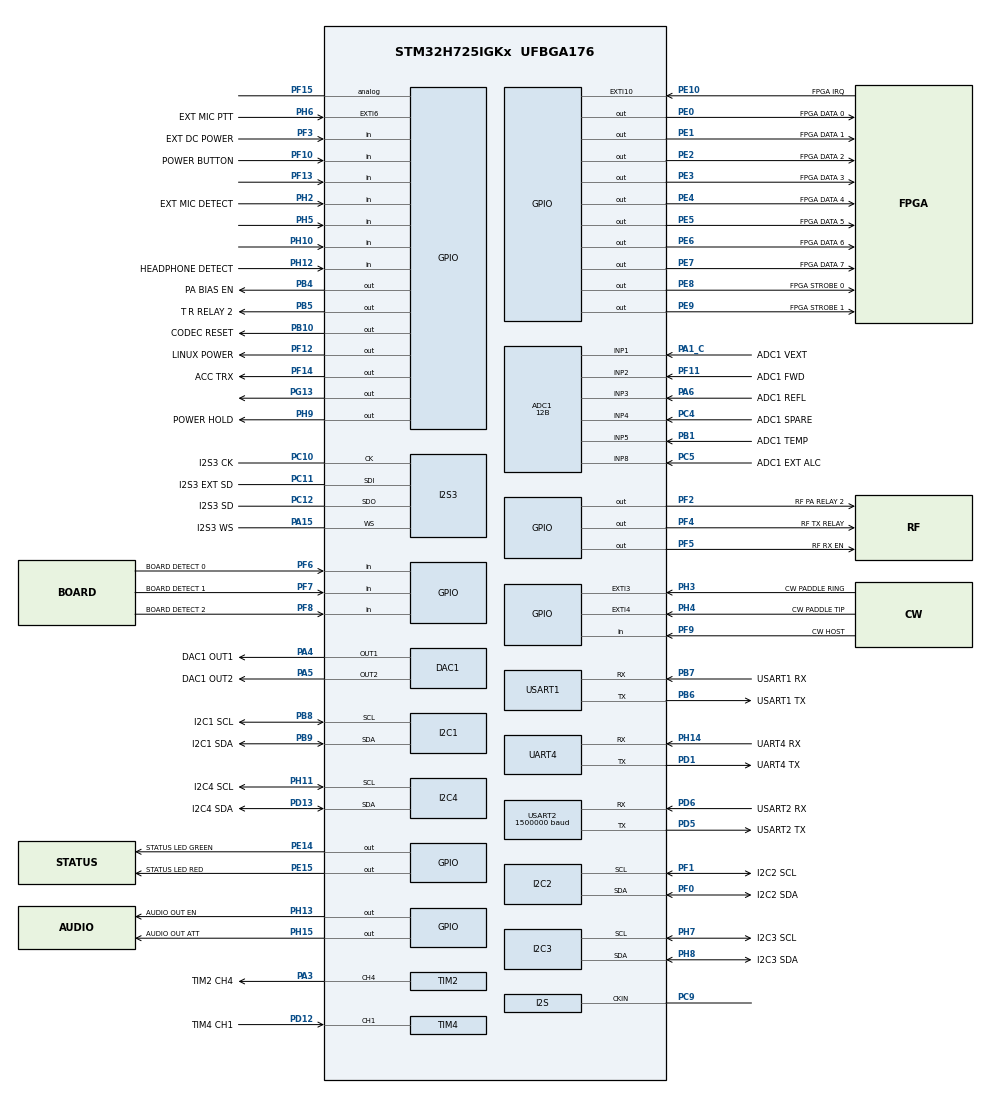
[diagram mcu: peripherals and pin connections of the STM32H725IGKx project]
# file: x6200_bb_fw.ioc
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ADC1.Channel-0\#ChannelRegularConversion=ADC_CHANNEL_1
ADC1.Channel-1\#ChannelRegularConversion=ADC_CHANNEL_2
ADC1.Channel-2\#ChannelRegularConversion=ADC_CHANNEL_3
ADC1.Channel-3\#ChannelRegularConversion=ADC_CHANNEL_4
ADC1.Channel-4\#ChannelRegularConversion=ADC_CHANNEL_5
ADC1.Channel-5\#ChannelRegularConversion=ADC_CHANNEL_8
ADC1.ClockPrescaler=ADC_CLOCK_ASYNC_DIV32
ADC1.ContinuousConvMode=ENABLE
ADC1.ConversionDataManagement=ADC_CONVERSIONDATA_DMA_CIRCULAR
ADC1.NbrOfConversion=6
ADC1.NbrOfConversionFlag=1
ADC1.OffsetNumber-0\#ChannelRegularConversion=ADC_OFFSET_NONE
ADC1.OffsetNumber-1\#ChannelRegularConversion=ADC_OFFSET_NONE
ADC1.OffsetNumber-2\#ChannelRegularConversion=ADC_OFFSET_NONE
ADC1.OffsetNumber-3\#ChannelRegularConversion=ADC_OFFSET_NONE
ADC1.OffsetNumber-4\#ChannelRegularConversion=ADC_OFFSET_NONE
ADC1.OffsetNumber-5\#ChannelRegularConversion=ADC_OFFSET_NONE
ADC1.OffsetSignedSaturation-0\#ChannelRegularConversion=DISABLE
ADC1.OffsetSignedSaturation-1\#ChannelRegularConversion=DISABLE
ADC1.OffsetSignedSaturation-2\#ChannelRegularConversion=DISABLE
ADC1.OffsetSignedSaturation-3\#ChannelRegularConversion=DISABLE
ADC1.OffsetSignedSaturation-4\#ChannelRegularConversion=DISABLE
ADC1.OffsetSignedSaturation-5\#ChannelRegularConversion=DISABLE
ADC1.Rank-0\#ChannelRegularConversion=1
ADC1.Rank-1\#ChannelRegularConversion=2
ADC1.Rank-2\#ChannelRegularConversion=3
ADC1.Rank-3\#ChannelRegularConversion=4
ADC1.Rank-4\#ChannelRegularConversion=5
ADC1.Rank-5\#ChannelRegularConversion=6
ADC1.Resolution=ADC_RESOLUTION_12B
ADC1.SamplingTime-0\#ChannelRegularConversion=ADC_SAMPLETIME_32CYCLES_5
ADC1.SamplingTime-1\#ChannelRegularConversion=ADC_SAMPLETIME_32CYCLES_5
ADC1.SamplingTime-2\#ChannelRegularConversion=ADC_SAMPLETIME_32CYCLES_5
ADC1.SamplingTime-3\#ChannelRegularConversion=ADC_SAMPLETIME_32CYCLES_5
ADC1.SamplingTime-4\#ChannelRegularConversion=ADC_SAMPLETIME_32CYCLES_5
ADC1.SamplingTime-5\#ChannelRegularConversion=ADC_SAMPLETIME_32CYCLES_5
ADC1.master=1
ARM.CMSIS-DSP.1.18.0.CMSISJjDSP=Source
CORTEX_M7.AccessPermission_Spec=MPU_REGION_FULL_ACCESS
CORTEX_M7.BaseAddress_Spec=0x30000000
CORTEX_M7.CPU_DCache=Enabled
CORTEX_M7.CPU_ICache=Enabled
CORTEX_M7.DisableExec_Spec=MPU_INSTRUCTION_ACCESS_DISABLE
CORTEX_M7.Enable_S-Cortex_Memory_Protection_Unit_Region1_Settings_S=__NULL
CORTEX_M7.Enable_S-Cortex_Memory_Protection_Unit_Region2_Settings_S=__NULL
CORTEX_M7.Enable_S-Cortex_Memory_Protection_Unit_Region3_Settings_S=__NULL
CORTEX_M7.Enable_S-Cortex_Memory_Protection_Unit_Region4_Settings_S=__NULL
CORTEX_M7.Enable_S-Cortex_Memory_Protection_Unit_Region5_Settings_S=__NULL
CORTEX_M7.Enable_Spec=MPU_REGION_ENABLE
CORTEX_M7.Size_Spec=MPU_REGION_SIZE_8KB
CORTEX_M7.SubRegionDisable_Spec=0x0
CORTEX_M7.TypeExtField_Spec=MPU_TEX_LEVEL1
CORTEX_M7.default_mode_Activation=1
CRC.InputDataFormat=CRC_INPUTDATA_FORMAT_WORDS
DAC1.DAC_Channel-DAC_OUT1=DAC_CHANNEL_1
DAC1.DAC_Channel-DAC_OUT2=DAC_CHANNEL_2
DAC1.DAC_Trigger-DAC_OUT1=DAC_TRIGGER_NONE
Dma.ADC1.2.Direction=DMA_PERIPH_TO_MEMORY
Dma.ADC1.2.EventEnable=DISABLE
Dma.ADC1.2.FIFOMode=DMA_FIFOMODE_DISABLE
Dma.ADC1.2.Instance=DMA1_Stream7
Dma.ADC1.2.MemDataAlignment=DMA_MDATAALIGN_HALFWORD
Dma.ADC1.2.MemInc=DMA_MINC_ENABLE
Dma.ADC1.2.Mode=DMA_CIRCULAR
Dma.ADC1.2.PeriphDataAlignment=DMA_PDATAALIGN_HALFWORD
Dma.ADC1.2.PeriphInc=DMA_PINC_DISABLE
Dma.ADC1.2.Polarity=HAL_DMAMUX_REQ_GEN_RISING
Dma.ADC1.2.Priority=DMA_PRIORITY_LOW
Dma.ADC1.2.RequestNumber=1
Dma.ADC1.2.SignalID=NONE
Dma.ADC1.2.SyncEnable=DISABLE
Dma.ADC1.2.SyncPolarity=HAL_DMAMUX_SYNC_NO_EVENT
Dma.ADC1.2.SyncRequestNumber=1
Dma.ADC1.2.SyncSignalID=NONE
Dma.Request0=SPI3_RX
Dma.Request1=SPI3_TX
Dma.Request2=ADC1
Dma.Request3=USART2_TX
Dma.Request4=USART1_TX
Dma.Request5=USART2_RX
Dma.SPI3_RX.0.Direction=DMA_PERIPH_TO_MEMORY
Dma.SPI3_RX.0.EventEnable=DISABLE
Dma.SPI3_RX.0.FIFOMode=DMA_FIFOMODE_ENABLE
Dma.SPI3_RX.0.FIFOThreshold=DMA_FIFO_THRESHOLD_HALFFULL
Dma.SPI3_RX.0.Instance=DMA1_Stream0
Dma.SPI3_RX.0.MemBurst=DMA_MBURST_SINGLE
Dma.SPI3_RX.0.MemDataAlignment=DMA_MDATAALIGN_WORD
Dma.SPI3_RX.0.MemInc=DMA_MINC_ENABLE
Dma.SPI3_RX.0.Mode=DMA_CIRCULAR
Dma.SPI3_RX.0.PeriphBurst=DMA_PBURST_SINGLE
Dma.SPI3_RX.0.PeriphDataAlignment=DMA_PDATAALIGN_WORD
Dma.SPI3_RX.0.PeriphInc=DMA_PINC_DISABLE
Dma.SPI3_RX.0.Polarity=HAL_DMAMUX_REQ_GEN_RISING
Dma.SPI3_RX.0.Priority=DMA_PRIORITY_HIGH
Dma.SPI3_RX.0.RequestNumber=1
Dma.SPI3_RX.0.SignalID=NONE
Dma.SPI3_RX.0.SyncEnable=DISABLE
Dma.SPI3_RX.0.SyncPolarity=HAL_DMAMUX_SYNC_NO_EVENT
Dma.SPI3_RX.0.SyncRequestNumber=1
Dma.SPI3_RX.0.SyncSignalID=NONE
Dma.SPI3_TX.1.Direction=DMA_MEMORY_TO_PERIPH
Dma.SPI3_TX.1.EventEnable=DISABLE
Dma.SPI3_TX.1.FIFOMode=DMA_FIFOMODE_ENABLE
Dma.SPI3_TX.1.FIFOThreshold=DMA_FIFO_THRESHOLD_HALFFULL
Dma.SPI3_TX.1.Instance=DMA1_Stream5
Dma.SPI3_TX.1.MemBurst=DMA_MBURST_SINGLE
Dma.SPI3_TX.1.MemDataAlignment=DMA_MDATAALIGN_WORD
Dma.SPI3_TX.1.MemInc=DMA_MINC_ENABLE
Dma.SPI3_TX.1.Mode=DMA_CIRCULAR
Dma.SPI3_TX.1.PeriphBurst=DMA_PBURST_SINGLE
Dma.SPI3_TX.1.PeriphDataAlignment=DMA_PDATAALIGN_WORD
Dma.SPI3_TX.1.PeriphInc=DMA_PINC_DISABLE
Dma.SPI3_TX.1.Polarity=HAL_DMAMUX_REQ_GEN_RISING
Dma.SPI3_TX.1.Priority=DMA_PRIORITY_HIGH
Dma.SPI3_TX.1.RequestNumber=1
Dma.SPI3_TX.1.SignalID=NONE
Dma.SPI3_TX.1.SyncEnable=DISABLE
Dma.SPI3_TX.1.SyncPolarity=HAL_DMAMUX_SYNC_NO_EVENT
Dma.SPI3_TX.1.SyncRequestNumber=1
Dma.SPI3_TX.1.SyncSignalID=NONE
Dma.USART1_TX.4.Direction=DMA_MEMORY_TO_PERIPH
Dma.USART1_TX.4.EventEnable=DISABLE
Dma.USART1_TX.4.FIFOMode=DMA_FIFOMODE_DISABLE
Dma.USART1_TX.4.Instance=DMA1_Stream2
Dma.USART1_TX.4.MemDataAlignment=DMA_MDATAALIGN_BYTE
Dma.USART1_TX.4.MemInc=DMA_MINC_ENABLE
Dma.USART1_TX.4.Mode=DMA_NORMAL
Dma.USART1_TX.4.PeriphDataAlignment=DMA_PDATAALIGN_BYTE
Dma.USART1_TX.4.PeriphInc=DMA_PINC_DISABLE
Dma.USART1_TX.4.Polarity=HAL_DMAMUX_REQ_GEN_RISING
Dma.USART1_TX.4.Priority=DMA_PRIORITY_LOW
Dma.USART1_TX.4.RequestNumber=1
Dma.USART1_TX.4.SignalID=NONE
Dma.USART1_TX.4.SyncEnable=DISABLE
Dma.USART1_TX.4.SyncPolarity=HAL_DMAMUX_SYNC_NO_EVENT
Dma.USART1_TX.4.SyncRequestNumber=1
Dma.USART1_TX.4.SyncSignalID=NONE
Dma.USART2_RX.5.Direction=DMA_PERIPH_TO_MEMORY
Dma.USART2_RX.5.EventEnable=DISABLE
Dma.USART2_RX.5.FIFOMode=DMA_FIFOMODE_DISABLE
Dma.USART2_RX.5.Instance=DMA1_Stream3
Dma.USART2_RX.5.MemDataAlignment=DMA_MDATAALIGN_BYTE
Dma.USART2_RX.5.MemInc=DMA_MINC_ENABLE
Dma.USART2_RX.5.Mode=DMA_CIRCULAR
Dma.USART2_RX.5.PeriphDataAlignment=DMA_PDATAALIGN_BYTE
Dma.USART2_RX.5.PeriphInc=DMA_PINC_DISABLE
Dma.USART2_RX.5.Polarity=HAL_DMAMUX_REQ_GEN_RISING
Dma.USART2_RX.5.Priority=DMA_PRIORITY_VERY_HIGH
Dma.USART2_RX.5.RequestNumber=1
Dma.USART2_RX.5.SignalID=NONE
Dma.USART2_RX.5.SyncEnable=DISABLE
Dma.USART2_RX.5.SyncPolarity=HAL_DMAMUX_SYNC_NO_EVENT
Dma.USART2_RX.5.SyncRequestNumber=1
Dma.USART2_RX.5.SyncSignalID=NONE
Dma.USART2_TX.3.Direction=DMA_MEMORY_TO_PERIPH
Dma.USART2_TX.3.EventEnable=DISABLE
Dma.USART2_TX.3.FIFOMode=DMA_FIFOMODE_DISABLE
Dma.USART2_TX.3.Instance=DMA1_Stream1
Dma.USART2_TX.3.MemDataAlignment=DMA_MDATAALIGN_BYTE
Dma.USART2_TX.3.MemInc=DMA_MINC_ENABLE
Dma.USART2_TX.3.Mode=DMA_NORMAL
Dma.USART2_TX.3.PeriphDataAlignment=DMA_PDATAALIGN_BYTE
Dma.USART2_TX.3.PeriphInc=DMA_PINC_DISABLE
Dma.USART2_TX.3.Polarity=HAL_DMAMUX_REQ_GEN_RISING
Dma.USART2_TX.3.Priority=DMA_PRIORITY_VERY_HIGH
Dma.USART2_TX.3.RequestNumber=1
Dma.USART2_TX.3.SignalID=NONE
Dma.USART2_TX.3.SyncEnable=DISABLE
Dma.USART2_TX.3.SyncPolarity=HAL_DMAMUX_SYNC_NO_EVENT
Dma.USART2_TX.3.SyncRequestNumber=1
Dma.USART2_TX.3.SyncSignalID=NONE
I2C1.Timing=0x307075B1
I2C2.Timing=0x307075B1
I2C3.CustomTiming=Enabled
I2C3.OwnAddress=0x72
I2C3.Timing=0x00B03FDB
I2C4.Timing=0x307075B1
I2S3.AudioFreq=I2S_AUDIOFREQ_48K
I2S3.DataFormat=I2S_DATAFORMAT_32B
I2S3.ErrorAudioFreq=0.0 %
I2S3.Instance=SPI$Index
I2S3.RealAudioFreq=48.0 KHz
Mcu.Family=STM32H7
Mcu.Name=STM32H725IGKx
Mcu.Package=UFBGA176
NVIC.DMA1_Stream0_IRQn=true\:2\:0\:true\:false\:true\:false\:true\:true
NVIC.DMA1_Stream1_IRQn=true\:5\:0\:true\:false\:true\:false\:true\:true
NVIC.DMA1_Stream2_IRQn=true\:9\:0\:true\:false\:true\:false\:true\:true
NVIC.DMA1_Stream3_IRQn=true\:5\:0\:true\:false\:true\:false\:true\:true
NVIC.DMA1_Stream5_IRQn=true\:2\:0\:true\:false\:true\:false\:true\:true
NVIC.DMA1_Stream7_IRQn=true\:1\:0\:true\:false\:true\:false\:true\:true
NVIC.EXTI15_10_IRQn=true\:0\:0\:true\:false\:true\:true\:true\:true
NVIC.EXTI3_IRQn=true\:1\:0\:true\:false\:true\:true\:true\:true
NVIC.EXTI4_IRQn=true\:1\:0\:true\:false\:true\:true\:true\:true
NVIC.EXTI9_5_IRQn=true\:3\:0\:true\:false\:true\:true\:true\:true
NVIC.I2C1_ER_IRQn=true\:8\:0\:true\:false\:true\:true\:true\:true
NVIC.I2C1_EV_IRQn=true\:8\:0\:true\:false\:true\:true\:true\:true
NVIC.I2C3_ER_IRQn=true\:5\:0\:true\:false\:true\:true\:true\:true
NVIC.I2C3_EV_IRQn=true\:5\:0\:true\:false\:true\:true\:true\:true
NVIC.PriorityGroup=NVIC_PRIORITYGROUP_4
NVIC.TIM17_IRQn=true\:3\:0\:true\:false\:true\:true\:true\:true
NVIC.TIM4_IRQn=true\:1\:0\:true\:false\:true\:true\:true\:true
NVIC.TIM6_DAC_IRQn=true\:8\:0\:true\:false\:true\:true\:true\:true
NVIC.TIM7_IRQn=true\:1\:0\:true\:false\:true\:true\:true\:true
NVIC.USART1_IRQn=true\:9\:0\:true\:false\:true\:true\:true\:true
NVIC.USART2_IRQn=true\:5\:0\:true\:false\:true\:true\:true\:true
PA15(JTDI).GPIO_Label=I2S3 WS
PA15(JTDI).GPIO_PuPd=GPIO_PULLUP
PA15(JTDI).GPIO_Speed=GPIO_SPEED_FREQ_VERY_HIGH
PA15(JTDI).Mode=Full_Duplex_Master
PA15(JTDI).Signal=I2S3_WS
PA1_C.GPIO_Label=ADC1 VEXT
PA1_C.Signal=ADCx_INP1
PA3.GPIO_Label=TIM2 CH4
PA3.Signal=S_TIM2_CH4
PA4.GPIO_Label=DAC1 OUT1
PA4.Signal=COMP_DAC11_group
PA5.GPIO_Label=DAC1 OUT2
PA5.Signal=COMP_DAC12_group
PA6.GPIO_Label=ADC1 REFL
PA6.Signal=ADCx_INP3
PB1.GPIO_Label=ADC1 TEMP
PB1.Signal=ADCx_INP5
PB10.GPIO_Label=CODEC RESET
PB10.Signal=GPIO_Output
PB4(NJTRST).GPIO_Label=PA BIAS EN
PB4(NJTRST).Signal=GPIO_Output
PB5.GPIO_Label=T R RELAY 2
PB5.Signal=GPIO_Output
PB6.GPIO_Label=USART1 TX
PB6.Mode=Asynchronous
PB6.Signal=USART1_TX
PB7.GPIO_Label=USART1 RX
PB7.Mode=Asynchronous
PB7.Signal=USART1_RX
PB8.GPIO_Label=I2C1 SCL
PB8.Mode=I2C
PB8.Signal=I2C1_SCL
PB9.GPIO_Label=I2C1 SDA
PB9.Mode=I2C
PB9.Signal=I2C1_SDA
PC10.GPIO_Label=I2S3 CK
PC10.GPIO_PuPd=GPIO_PULLUP
PC10.GPIO_Speed=GPIO_SPEED_FREQ_VERY_HIGH
PC10.Mode=Full_Duplex_Master
PC10.Signal=I2S3_CK
PC11.GPIO_Label=I2S3 EXT SD
PC11.GPIO_PuPd=GPIO_PULLUP
PC11.GPIO_Speed=GPIO_SPEED_FREQ_VERY_HIGH
PC11.Mode=Full_Duplex_Master
PC11.Signal=I2S3_SDI
PC12.GPIO_Label=I2S3 SD
PC12.GPIO_PuPd=GPIO_PULLUP
PC12.GPIO_Speed=GPIO_SPEED_FREQ_VERY_HIGH
PC12.Mode=Full_Duplex_Master
PC12.Signal=I2S3_SDO
PC4.GPIO_Label=ADC1 SPARE
PC4.Signal=ADCx_INP4
PC5.GPIO_Label=ADC1 EXT ALC
PC5.Signal=ADCx_INP8
PC9.Mode=Audio_ClockIn
PC9.Signal=I2S_CKIN
PD1.GPIO_Label=UART4 TX
PD1.Mode=Asynchronous
PD1.Signal=UART4_TX
PD12.GPIO_Label=TIM4 CH1
PD12.Signal=S_TIM4_CH1
PD13.GPIO_Label=I2C4 SDA
PD13.Mode=I2C
PD13.Signal=I2C4_SDA
PD5.GPIO_Label=USART2 TX
PD5.Mode=Asynchronous
PD5.Signal=USART2_TX
PD6.GPIO_Label=USART2 RX
PD6.Mode=Asynchronous
PD6.Signal=USART2_RX
PE0.GPIO_Label=FPGA DATA 0
PE0.GPIO_PuPd=GPIO_PULLUP
PE0.GPIO_Speed=GPIO_SPEED_FREQ_MEDIUM
PE0.Signal=GPIO_Output
PE1.GPIO_Label=FPGA DATA 1
PE1.GPIO_PuPd=GPIO_PULLUP
PE1.GPIO_Speed=GPIO_SPEED_FREQ_MEDIUM
PE1.Signal=GPIO_Output
PE10.GPIO_Label=FPGA IRQ
PE10.GPIO_PuPd=GPIO_PULLUP
PE10.Signal=GPXTI10
PE14.GPIO_Label=STATUS LED GREEN
PE14.GPIO_ModeDefaultOutputPP=GPIO_MODE_OUTPUT_OD
PE14.GPIO_PuPd=GPIO_NOPULL
PE14.PinState=GPIO_PIN_SET
PE14.Signal=GPIO_Output
PE15.GPIO_Label=STATUS LED RED
PE15.GPIO_ModeDefaultOutputPP=GPIO_MODE_OUTPUT_OD
PE15.GPIO_PuPd=GPIO_NOPULL
PE15.PinState=GPIO_PIN_SET
PE15.Signal=GPIO_Output
PE2.GPIO_Label=FPGA DATA 2
PE2.GPIO_PuPd=GPIO_PULLUP
PE2.GPIO_Speed=GPIO_SPEED_FREQ_MEDIUM
PE2.Signal=GPIO_Output
PE3.GPIO_Label=FPGA DATA 3
PE3.GPIO_PuPd=GPIO_PULLUP
PE3.GPIO_Speed=GPIO_SPEED_FREQ_MEDIUM
PE3.Signal=GPIO_Output
PE4.GPIO_Label=FPGA DATA 4
PE4.GPIO_PuPd=GPIO_PULLUP
PE4.GPIO_Speed=GPIO_SPEED_FREQ_MEDIUM
PE4.Signal=GPIO_Output
PE5.GPIO_Label=FPGA DATA 5
PE5.GPIO_PuPd=GPIO_PULLUP
PE5.GPIO_Speed=GPIO_SPEED_FREQ_MEDIUM
PE5.Signal=GPIO_Output
PE6.GPIO_Label=FPGA DATA 6
PE6.GPIO_PuPd=GPIO_PULLUP
PE6.GPIO_Speed=GPIO_SPEED_FREQ_MEDIUM
PE6.Signal=GPIO_Output
PE7.GPIO_Label=FPGA DATA 7
PE7.GPIO_PuPd=GPIO_PULLUP
PE7.GPIO_Speed=GPIO_SPEED_FREQ_MEDIUM
PE7.Signal=GPIO_Output
PE8.GPIO_Label=FPGA STROBE 0
PE8.GPIO_PuPd=GPIO_PULLUP
PE8.GPIO_Speed=GPIO_SPEED_FREQ_MEDIUM
PE8.Signal=GPIO_Output
PE9.GPIO_Label=FPGA STROBE 1
PE9.GPIO_PuPd=GPIO_PULLUP
PE9.GPIO_Speed=GPIO_SPEED_FREQ_MEDIUM
PE9.Signal=GPIO_Output
PF0.GPIO_Label=I2C2 SDA
PF0.Mode=I2C
PF0.Signal=I2C2_SDA
PF1.GPIO_Label=I2C2 SCL
PF1.Mode=I2C
PF1.Signal=I2C2_SCL
PF10.GPIO_Label=POWER BUTTON
PF10.GPIO_PuPd=GPIO_PULLUP
PF10.Signal=GPIO_Input
PF11.GPIO_Label=ADC1 FWD
PF11.Mode=IN2-Single-Ended
PF11.Signal=ADC1_INP2
PF12.GPIO_Label=LINUX POWER
PF12.PinState=GPIO_PIN_SET
PF12.Signal=GPIO_Output
PF13.GPIO_PuPd=GPIO_PULLUP
PF13.Signal=GPIO_Input
PF14.GPIO_Label=ACC TRX
PF14.GPIO_PuPd=GPIO_PULLUP
PF14.Signal=GPIO_Output
PF15.Signal=GPIO_Analog
PF2.GPIO_Label=RF PA RELAY 2
PF2.Signal=GPIO_Output
PF3.GPIO_Label=EXT DC POWER
PF3.Signal=GPIO_Input
PF4.GPIO_Label=RF TX RELAY
PF4.Signal=GPIO_Output
PF5.GPIO_Label=RF RX EN
PF5.Signal=GPIO_Output
PF6.GPIO_Label=BOARD DETECT 0
PF6.GPIO_PuPd=GPIO_PULLUP
PF6.Signal=GPIO_Input
PF7.GPIO_Label=BOARD DETECT 1
PF7.GPIO_PuPd=GPIO_PULLUP
PF7.Signal=GPIO_Input
PF8.GPIO_Label=BOARD DETECT 2
PF8.GPIO_PuPd=GPIO_PULLUP
PF8.Signal=GPIO_Input
PF9.GPIO_Label=CW HOST
PF9.GPIO_PuPd=GPIO_PULLUP
PF9.Signal=GPIO_Input
PG13.PinState=GPIO_PIN_SET
PG13.Signal=GPIO_Output
PH0-OSC_IN.Mode=HSE-External-Oscillator
PH0-OSC_IN.Signal=RCC_OSC_IN
PH1-OSC_OUT.Mode=HSE-External-Oscillator
PH1-OSC_OUT.Signal=RCC_OSC_OUT
PH10.GPIO_PuPd=GPIO_PULLUP
PH10.Signal=GPIO_Input
PH11.GPIO_Label=I2C4 SCL
PH11.Mode=I2C
PH11.Signal=I2C4_SCL
PH12.GPIO_Label=HEADPHONE DETECT
PH12.GPIO_PuPd=GPIO_PULLUP
PH12.Signal=GPIO_Input
PH13.GPIO_Label=AUDIO OUT EN
PH13.Signal=GPIO_Output
PH14.GPIO_Label=UART4 RX
PH14.Mode=Asynchronous
PH14.Signal=UART4_RX
PH15.GPIO_Label=AUDIO OUT ATT
PH15.Signal=GPIO_Output
PH2.GPIO_Label=EXT MIC DETECT
PH2.GPIO_PuPd=GPIO_PULLUP
PH2.Signal=GPIO_Input
PH3.GPIO_Label=CW PADDLE RING
PH3.GPIO_ModeDefaultEXTI=GPIO_MODE_IT_RISING_FALLING
PH3.GPIO_PuPd=GPIO_PULLUP
PH3.Signal=GPXTI3
PH4.GPIO_Label=CW PADDLE TIP
PH4.GPIO_ModeDefaultEXTI=GPIO_MODE_IT_RISING_FALLING
PH4.GPIO_PuPd=GPIO_PULLUP
PH4.Signal=GPXTI4
PH5.Signal=GPIO_Input
PH6.GPIO_Label=EXT MIC PTT
PH6.GPIO_ModeDefaultEXTI=GPIO_MODE_IT_RISING_FALLING
PH6.GPIO_PuPd=GPIO_PULLUP
PH6.Signal=GPXTI6
PH7.GPIO_Label=I2C3 SCL
PH7.Mode=I2C
PH7.Signal=I2C3_SCL
PH8.GPIO_Label=I2C3 SDA
PH8.Mode=I2C
PH8.Signal=I2C3_SDA
PH9.GPIO_Label=POWER HOLD
PH9.PinState=GPIO_PIN_SET
PH9.Signal=GPIO_Output
ProjectManager.HeapSize=0x200
ProjectManager.StackSize=0x400
ProjectManager.TargetToolchain=CMake
RCC.ADCFreq_Value=96000671.38671875
RCC.APB1Freq_Value=120000000
RCC.APB2Freq_Value=120000000
RCC.APB3Freq_Value=120000000
RCC.APB4Freq_Value=120000000
RCC.CortexFreq_Value=480000000
RCC.D1PPRE=RCC_APB3_DIV2
RCC.D2PPRE1=RCC_APB1_DIV2
RCC.D2PPRE2=RCC_APB2_DIV2
RCC.D3PPRE=RCC_APB4_DIV2
RCC.DIVM1=5
RCC.DIVM2=2
RCC.DIVN1=96
RCC.DIVN2=15
RCC.DIVP1=1
RCC.EXTERNAL_CLOCK_VALUE=12288000
RCC.HCLKFreq_Value=240000000
RCC.HPRE=RCC_HCLK_DIV2
RCC.HSE_VALUE=25000000
RCC.PLL2FRACN=2950
RCC.PLLFRACN=0
RCC.PLLSourceVirtual=RCC_PLLSOURCE_HSE
RCC.RCC_TIM_PRescaler_Selection=RCC_TIMPRES_DESACTIVATED
RCC.SPI123CLockSelection=RCC_SPI123CLKSOURCE_PIN
RCC.SYSCLKFreq_VALUE=480000000
RCC.SYSCLKSource=RCC_SYSCLKSOURCE_PLLCLK
RCC.SupplySource=PWR_SMPS_2V5_SUPPLIES_EXT_AND_LDO
RCC.USBFreq_Value=240000000
SH.ADCx_INP1.0=ADC1_INP1,IN1-Single-Ended
SH.ADCx_INP3.0=ADC1_INP3,IN3-Single-Ended
SH.ADCx_INP4.0=ADC1_INP4,IN4-Single-Ended
SH.ADCx_INP5.0=ADC1_INP5,IN5-Single-Ended
SH.ADCx_INP8.0=ADC1_INP8,IN8-Single-Ended
SH.COMP_DAC11_group.0=DAC1_OUT1,DAC_OUT1
SH.COMP_DAC12_group.0=DAC1_OUT2,DAC_OUT2
SH.S_TIM2_CH4.0=TIM2_CH4,PWM Generation4 CH4
SH.S_TIM4_CH1.0=TIM4_CH1,PWM_Input_1
TIM17.Period=99
TIM17.Prescaler=119
TIM2.Channel-PWM\ Generation4\ CH4=TIM_CHANNEL_4
TIM2.Period=47999
TIM2.Pulse-PWM\ Generation4\ CH4=24000
TIM4.Prescaler=9
TIM6.Period=199
TIM6.Prescaler=11999
TIM6.TIM_MasterOutputTrigger=TIM_TRGO_UPDATE
TIM7.Period=799
TIM7.Prescaler=99
USART1.VirtualMode-Asynchronous=VM_ASYNC
USART2.BaudRate=1500000
USART2.FIFOMode=FIFOMODE_ENABLE
USART2.TXFIFOThreshold=TXFIFO_THRESHOLD_HALFFULL
USART2.VirtualMode-Asynchronous=VM_ASYNC
VP_ARM.CMSIS-DSP_VS_CMSISJjDSP_1.18.0_1.18.0.Mode=CMSISJjDSP
VP_CORDIC_VS_CORDIC.Mode=CORDIC_Activate
VP_CRC_VS_CRC.Mode=CRC_Activate
VP_MEMORYMAP_VS_MEMORYMAP.Mode=CurAppReg
VP_TIM17_VS_ClockSourceINT.Mode=Enable_Timer
VP_TIM4_VS_ClockSourceINT.Mode=Internal
VP_TIM6_VS_ClockSourceINT.Mode=Enable_Timer
VP_TIM7_VS_ClockSourceINT.Mode=Enable_Timer
board=custom

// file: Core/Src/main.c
/* USER CODE BEGIN Header */
/**
  ******************************************************************************
  * @file           : main.c
  * @brief          : Main program body
  ******************************************************************************
  * @attention
  *
  * Copyright (c) 2026 STMicroelectronics.
  * All rights reserved.
  *
  * This software is licensed under terms that can be found in the LICENSE file
  * in the root directory of this software component.
  * If no LICENSE file comes with this software, it is provided AS-IS.
  *
  ******************************************************************************
  */
/* USER CODE END Header */
#include "main.h"
#include "adc.h"
#include "cordic.h"
#include "crc.h"
#include "dac.h"
#include "dma.h"
#include "i2c.h"
#include "i2s.h"
#include "tim.h"
#include "usart.h"
#include "gpio.h"

/* USER CODE BEGIN Includes */
#include "app_main.h"
/* USER CODE END Includes */

void SystemClock_Config(void);
static void MPU_Config(void);

int main(void)
{

  /* MPU Configuration--------------------------------------------------------*/
  MPU_Config();

  /* Enable the CPU Cache */

  /* Enable I-Cache---------------------------------------------------------*/
  SCB_EnableICache();

  /* Enable D-Cache---------------------------------------------------------*/
  SCB_EnableDCache();

  /* MCU Configuration--------------------------------------------------------*/

  /* Reset of all peripherals, Initializes the Flash interface and the Systick. */
  HAL_Init();

  /* Configure the system clock */
  SystemClock_Config();

  /* Initialize all configured peripherals */
  MX_GPIO_Init();
  MX_DMA_Init();
  MX_ADC1_Init();
  MX_DAC1_Init();
  MX_I2C1_Init();
  MX_I2C2_Init();
  MX_I2C3_Init();
  MX_I2C4_Init();
  MX_TIM6_Init();
  MX_UART4_Init();
  MX_USART1_UART_Init();
  MX_USART2_UART_Init();
  MX_I2S3_Init();
  MX_TIM2_Init();
  MX_TIM4_Init();
  MX_TIM7_Init();
  MX_TIM17_Init();
  MX_CRC_Init();
  MX_CORDIC_Init();
  /* USER CODE BEGIN 2 */
  App_Main();
  /* USER CODE END 2 */

  /* Infinite loop */
  while (1)
  {

  }
}

void SystemClock_Config(void)
{
  RCC_OscInitTypeDef RCC_OscInitStruct = {0};
  RCC_ClkInitTypeDef RCC_ClkInitStruct = {0};

  /** Supply configuration update enable
  */
  HAL_PWREx_ConfigSupply(PWR_SMPS_2V5_SUPPLIES_EXT_AND_LDO);

  /** Configure the main internal regulator output voltage
  */
  __HAL_PWR_VOLTAGESCALING_CONFIG(PWR_REGULATOR_VOLTAGE_SCALE0);

  while(!__HAL_PWR_GET_FLAG(PWR_FLAG_VOSRDY)) {}

  /** Initializes the RCC Oscillators according to the specified parameters
  * in the RCC_OscInitTypeDef structure.
  */
  RCC_OscInitStruct.OscillatorType = RCC_OSCILLATORTYPE_HSE;
  RCC_OscInitStruct.HSEState = RCC_HSE_ON;
  RCC_OscInitStruct.PLL.PLLState = RCC_PLL_ON;
  RCC_OscInitStruct.PLL.PLLSource = RCC_PLLSOURCE_HSE;
  RCC_OscInitStruct.PLL.PLLM = 5;
  RCC_OscInitStruct.PLL.PLLN = 96;
  RCC_OscInitStruct.PLL.PLLP = 1;
  RCC_OscInitStruct.PLL.PLLQ = 2;
  RCC_OscInitStruct.PLL.PLLR = 2;
  RCC_OscInitStruct.PLL.PLLRGE = RCC_PLL1VCIRANGE_2;
  RCC_OscInitStruct.PLL.PLLVCOSEL = RCC_PLL1VCOWIDE;
  RCC_OscInitStruct.PLL.PLLFRACN = 0;
  if (HAL_RCC_OscConfig(&RCC_OscInitStruct) != HAL_OK)
  {
    Error_Handler();
  }

  /** Initializes the CPU, AHB and APB buses clocks
  */
  RCC_ClkInitStruct.ClockType = RCC_CLOCKTYPE_HCLK|RCC_CLOCKTYPE_SYSCLK
                              |RCC_CLOCKTYPE_PCLK1|RCC_CLOCKTYPE_PCLK2
                              |RCC_CLOCKTYPE_D3PCLK1|RCC_CLOCKTYPE_D1PCLK1;
  RCC_ClkInitStruct.SYSCLKSource = RCC_SYSCLKSOURCE_PLLCLK;
  RCC_ClkInitStruct.SYSCLKDivider = RCC_SYSCLK_DIV1;
  RCC_ClkInitStruct.AHBCLKDivider = RCC_HCLK_DIV2;
  RCC_ClkInitStruct.APB3CLKDivider = RCC_APB3_DIV2;
  RCC_ClkInitStruct.APB1CLKDivider = RCC_APB1_DIV2;
  RCC_ClkInitStruct.APB2CLKDivider = RCC_APB2_DIV2;
  RCC_ClkInitStruct.APB4CLKDivider = RCC_APB4_DIV2;

  if (HAL_RCC_ClockConfig(&RCC_ClkInitStruct, FLASH_LATENCY_3) != HAL_OK)
  {
    Error_Handler();
  }
}

 /* MPU Configuration */

void MPU_Config(void)
{
  MPU_Region_InitTypeDef MPU_InitStruct = {0};

  /* Disables the MPU */
  HAL_MPU_Disable();

  /** Initializes and configures the Region and the memory to be protected
  */
  MPU_InitStruct.Enable = MPU_REGION_ENABLE;
  MPU_InitStruct.Number = MPU_REGION_NUMBER0;
  MPU_InitStruct.BaseAddress = 0x30000000;
  MPU_InitStruct.Size = MPU_REGION_SIZE_8KB;
  MPU_InitStruct.SubRegionDisable = 0x0;
  MPU_InitStruct.TypeExtField = MPU_TEX_LEVEL1;
  MPU_InitStruct.AccessPermission = MPU_REGION_FULL_ACCESS;
  MPU_InitStruct.DisableExec = MPU_INSTRUCTION_ACCESS_DISABLE;
  MPU_InitStruct.IsShareable = MPU_ACCESS_SHAREABLE;
  MPU_InitStruct.IsCacheable = MPU_ACCESS_NOT_CACHEABLE;
  MPU_InitStruct.IsBufferable = MPU_ACCESS_NOT_BUFFERABLE;

  HAL_MPU_ConfigRegion(&MPU_InitStruct);
  /* Enables the MPU */
  HAL_MPU_Enable(MPU_PRIVILEGED_DEFAULT);

}

void Error_Handler(void)
{
  __disable_irq();
  while (1)
  {
  }
}
